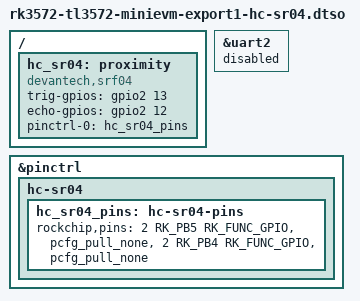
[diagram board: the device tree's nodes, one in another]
// SPDX-License-Identifier: (GPL-2.0+ OR MIT)
/*
 * Copyright (c) 2026 unifreq <flippy@sina.com>
 *
 * TL3572-MiniEVM EXPORT1+2 替代组合 overlay：原EXPORT1 pint15/17 (UART2) 改为适配HC-SR04型超声波测距传感器
 *
 * 占用引脚：
 *   EXPORT1(CON13): pin 15 = GPIO2_B5 ==> 传感器Trig引脚
 *                   pin 17 = GPIO2_B4 ==> 传感器Echo引脚
 * 互斥关系（本 overlay 会关闭以下默认项）：
 *   EXPORT1 pin15/17/19 组：默认 UART2
 */

/dts-v1/;
/plugin/;

#include <dt-bindings/gpio/gpio.h>
#include <dt-bindings/pinctrl/rockchip.h>

/ {
	/* 关闭默认的 UART2（占用 EXPORT1 pin15/17/19） */
	fragment@0 {
		target = <&uart2>;

		__overlay__ {
			status = "disabled";
		};
	};

	/* HC-SR04 超声波测距传感器（drivers/iio/proximity/srf04） */
	fragment@1 {
		target-path = "/";

		__overlay__ {
			hc_sr04: proximity {
				compatible = "devantech,srf04";
				/* EXPORT1 pin15 = GPIO2_B5 = gpio2 13 ==> Trig */
				trig-gpios = <&gpio2 13 GPIO_ACTIVE_HIGH>;
				/* EXPORT1 pin17 = GPIO2_B4 = gpio2 12 ==> Echo */
				echo-gpios = <&gpio2 12 GPIO_ACTIVE_HIGH>;
				pinctrl-names = "default";
				pinctrl-0 = <&hc_sr04_pins>;
				status = "okay";
			};
		};
	};

	/* 将 GPIO2_B4/B5 从 UART2 复用功能切回 GPIO */
	fragment@2 {
		target = <&pinctrl>;

		__overlay__ {
			hc-sr04 {
				hc_sr04_pins: hc-sr04-pins {
					rockchip,pins =
						/* GPIO2_B5 (Trig) */
						<2 RK_PB5 RK_FUNC_GPIO &pcfg_pull_none>,
						/* GPIO2_B4 (Echo) */
						<2 RK_PB4 RK_FUNC_GPIO &pcfg_pull_none>;
				};
			};
		};
	};
};
